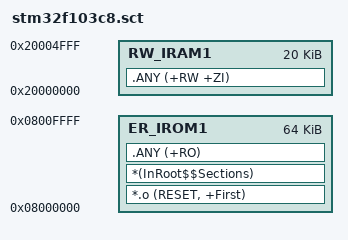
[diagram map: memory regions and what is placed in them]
; ARMCLANG scatter file for STM32F103C8.
; Matches src/platform/board/stm32f103c8/linker_scripts/link.lds:
; ROM 0x08000000, 0x10000 bytes; RAM 0x20000000, 0x5000 bytes.

LR_IROM1 0x08000000 0x10000
{
    ER_IROM1 0x08000000 0x10000
    {
        *.o (RESET, +First)
        *(InRoot$$Sections)
        .ANY (+RO)
    }

    ; The startup STACK input section reserves 0x400 bytes at runtime.
    RW_IRAM1 0x20000000 0x5000
    {
        .ANY (+RW +ZI)
    }
    ARM_LIB_STACK 0x20004C00 EMPTY 0x400
}
